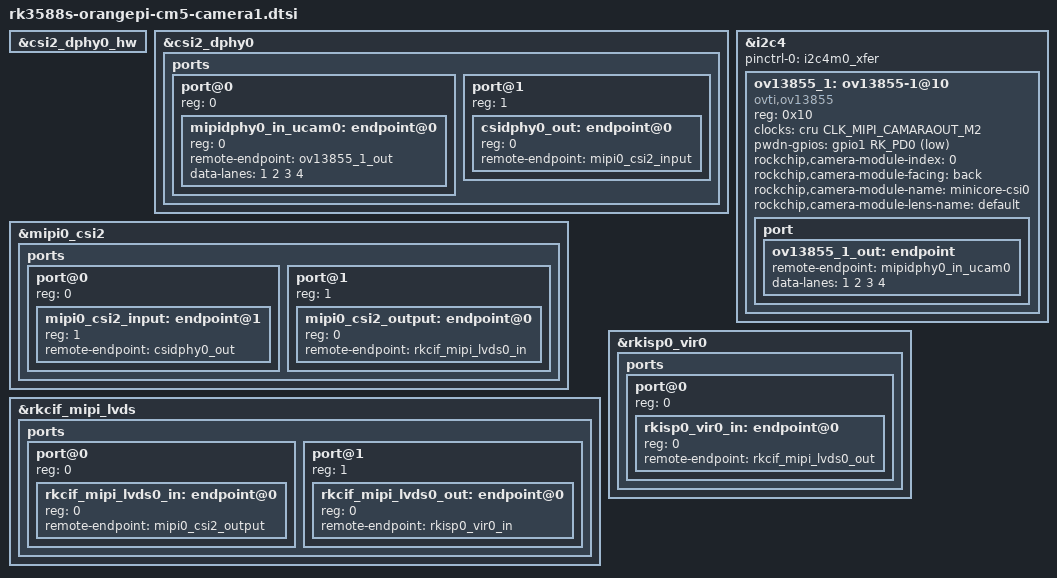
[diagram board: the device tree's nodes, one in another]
// SPDX-License-Identifier: (GPL-2.0+ OR MIT)
/*
 * Copyright (c) 2021 Rockchip Electronics Co., Ltd.
 * MiniCoreV2 CSI0-4lan: OV13855 on csi2_dphy0 → mipi0_csi2 (user verified 2026-10-03)
 */

&csi2_dphy0_hw {
	status = "okay";
};

&csi2_dphy0 {
	status = "okay";
	ports {
		#address-cells = <1>;
		#size-cells = <0>;
		port@0 {
			reg = <0>;
			#address-cells = <1>;
			#size-cells = <0>;

			mipidphy0_in_ucam0: endpoint@0 {
				reg = <0>;
				remote-endpoint = <&ov13855_1_out>;
				data-lanes = <1 2 3 4>;
			};
		};
		port@1 {
			reg = <1>;
			#address-cells = <1>;
			#size-cells = <0>;
			csidphy0_out: endpoint@0 {
				reg = <0>;
				remote-endpoint = <&mipi0_csi2_input>;
			};
		};
	};
};

&i2c4 {
	status = "okay";
	pinctrl-names = "default";
	pinctrl-0 = <&i2c4m0_xfer>;

	ov13855_1: ov13855-1@10 {
		status = "okay";
		compatible = "ovti,ov13855";
		reg = <0x10>;
		clocks = <&cru CLK_MIPI_CAMARAOUT_M2>;
		clock-names = "xvclk";
		pwdn-gpios = <&gpio1 RK_PD0 GPIO_ACTIVE_LOW>;
		rockchip,camera-module-index = <0>;
		rockchip,camera-module-facing = "back";
		rockchip,camera-module-name = "minicore-csi0";
		rockchip,camera-module-lens-name = "default";
		port {
			ov13855_1_out: endpoint {
				remote-endpoint = <&mipidphy0_in_ucam0>;
				data-lanes = <1 2 3 4>;
			};
		};
	};
};

&mipi0_csi2 {
	status = "okay";
	ports {
		#address-cells = <1>;
		#size-cells = <0>;
		port@0 {
			reg = <0>;
			#address-cells = <1>;
			#size-cells = <0>;
			mipi0_csi2_input: endpoint@1 {
				reg = <1>;
				remote-endpoint = <&csidphy0_out>;
			};
		};
		port@1 {
			reg = <1>;
			#address-cells = <1>;
			#size-cells = <0>;
			mipi0_csi2_output: endpoint@0 {
				reg = <0>;
				remote-endpoint = <&rkcif_mipi_lvds0_in>;
			};
		};
	};
};

&rkcif_mipi_lvds {
	status = "okay";
	ports {
		#address-cells = <1>;
		#size-cells = <0>;
		port@0 {
			reg = <0>;
			#address-cells = <1>;
			#size-cells = <0>;
			rkcif_mipi_lvds0_in: endpoint@0 {
				reg = <0>;
				remote-endpoint = <&mipi0_csi2_output>;
			};
		};
		port@1 {
			reg = <1>;
			#address-cells = <1>;
			#size-cells = <0>;
			rkcif_mipi_lvds0_out: endpoint@0 {
				reg = <0>;
				remote-endpoint = <&rkisp0_vir0_in>;
			};
		};
	};
};

&rkisp0_vir0 {
	status = "okay";
	ports {
		#address-cells = <1>;
		#size-cells = <0>;
		port@0 {
			reg = <0>;
			#address-cells = <1>;
			#size-cells = <0>;
			rkisp0_vir0_in: endpoint@0 {
				reg = <0>;
				remote-endpoint = <&rkcif_mipi_lvds0_out>;
			};
		};
	};
};
